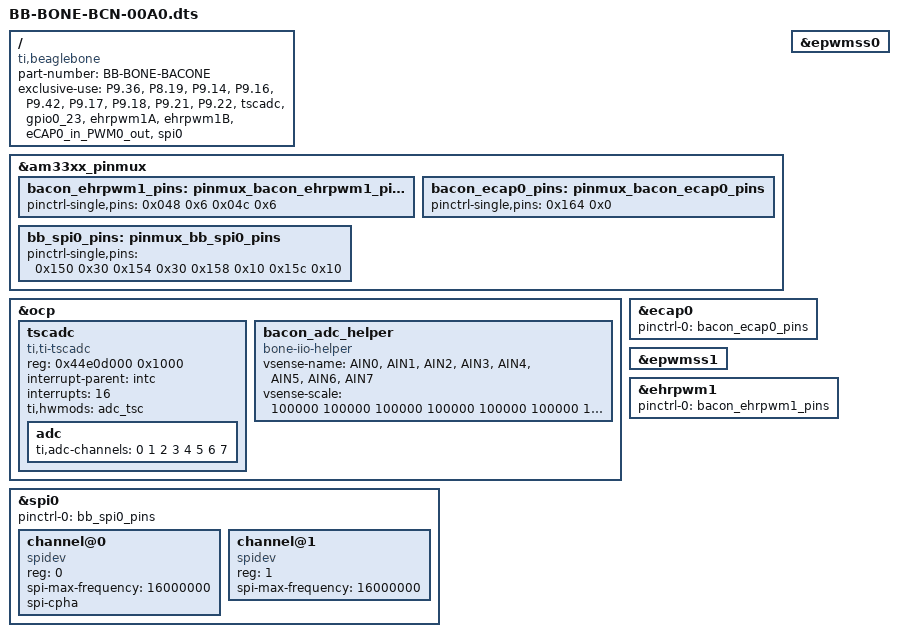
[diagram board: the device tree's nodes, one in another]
/*
 * Copyright (C) 2013 Circuit Co.
 *
 * This program is free software; you can redistribute it and/or modify
 * it under the terms of the GNU General Public License version 2 as
 * published by the Free Software Foundation.
 */
/dts-v1/;
/plugin/;

/ {
	compatible = "ti,beaglebone", "ti,beaglebone-black";

	/* identification */
	part-number = "BB-BONE-BACONE";

	/* state the resources this cape uses */
	exclusive-use =
		/* the pin header uses */
		"P9.36",	/* AIN5 */
		"P8.19",	/* gpio-keys: gpio0_23 */
		"P9.14",	/* pwm: ehrpwm1A */
		"P9.16",	/* pwm: ehrpwm1B */
		"P9.42",	/* pwm: eCAP0_in_PWM0_out */
		"P9.17",	/* spi0_cs0 */
		"P9.18",	/* spi0_d1 */
		"P9.21",	/* spi0_d0 */
		"P9.22",	/* spi0_sclk */
		/* the hardware IP uses */
		"tscadc",
		"gpio0_23",
		"ehrpwm1A",
		"ehrpwm1B",
		"eCAP0_in_PWM0_out",
		"spi0";

	fragment@0 {
		target = <&am33xx_pinmux>;
		__overlay__ {

			bacon_ehrpwm1_pins: pinmux_bacon_ehrpwm1_pins {
				pinctrl-single,pins = <
					0x048  0x6	/* P9_14 (ZCZ ball U14) | MODE 6 */
					0x04c  0x6	/* P9_16 (ZCZ ball T14) | MODE 6 */
				>;
			};

			bacon_ecap0_pins: pinmux_bacon_ecap0_pins {
				pinctrl-single,pins = <
					0x164  0x0	/* P9_42 (ZCZ ball C18) | MODE 0 */
				>;
			};

			bb_spi0_pins: pinmux_bb_spi0_pins {
				pinctrl-single,pins = <
					0x150 0x30	/* spi0_sclk.spi0_sclk, INPUT_PULLUP | MODE0 */
					0x154 0x30	/* spi0_d0.spi0_d0, INPUT_PULLUP | MODE0 */
					0x158 0x10	/* spi0_d1.spi0_d1, OUTPUT_PULLUP | MODE0 */
					0x15c 0x10	/* spi0_cs0.spi0_cs0, OUTPUT_PULLUP | MODE0 */
				>;
			};
		};
	};

	fragment@1 {
		target = <&ocp>;
		__overlay__ {
			/* avoid stupid warning */
			#address-cells = <1>;
			#size-cells = <1>;

			tscadc {
				compatible = "ti,ti-tscadc";
				reg = <0x44e0d000 0x1000>;

				interrupt-parent = <&intc>;
				interrupts = <16>;
				ti,hwmods = "adc_tsc";
				status = "okay";

				adc {
					ti,adc-channels = <0 1 2 3 4 5 6 7>; /* 8 channels (but only #5 is used) */
				};
			};

			bacon_adc_helper {
				compatible = "bone-iio-helper";
				vsense-name  = "AIN0", "AIN1", "AIN2", "AIN3", "AIN4", "AIN5", "AIN6", "AIN7";
				/* report micro-volts */
				vsense-scale = <100000  100000  100000  100000  100000  100000  100000  100000>;
				status = "okay";
			};
		};
	};

	fragment@3 {
		target = <&epwmss0>;
		__overlay__ {
			status = "okay";
		};
	};

	fragment@4 {
		target = <&ecap0>;
		__overlay__ {
			pinctrl-names = "default";
			pinctrl-0 = <&bacon_ecap0_pins>;
			status = "okay";
		};
	};

	fragment@5 {
		target = <&epwmss1>;
		__overlay__ {
			status = "okay";
		};
	};

	fragment@6 {
		target = <&ehrpwm1>;
		__overlay__ {
			pinctrl-names = "default";
			pinctrl-0 = <&bacon_ehrpwm1_pins>;
			status = "okay";
		};
	};

	fragment@8 {
		target = <&spi0>;	/* spi0 is numbered correctly */
		__overlay__ {
			#address-cells = <1>;
			#size-cells = <0>;

			status = "okay";
			pinctrl-names = "default";
			pinctrl-0 = <&bb_spi0_pins>;


			channel@0 {
				#address-cells = <1>;
				#size-cells = <0>;

				compatible = "spidev";

				reg = <0>;
				spi-max-frequency = <16000000>;
				spi-cpha;
			};


			channel@1 {
				#address-cells = <1>;
				#size-cells = <0>;

				compatible = "spidev";

				reg = <1>;
				spi-max-frequency = <16000000>;
			};
		};
	};

};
